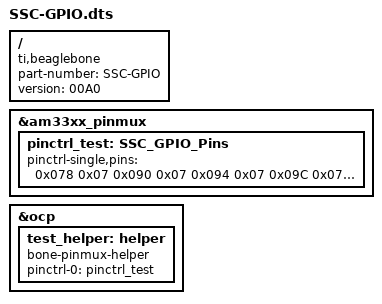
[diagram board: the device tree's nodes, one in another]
/*  
* Copyright (C) 2012 Texas Instruments Incorporated - http://www.ti.com/
*
* This program is free software; you can redistribute it and/or modify
* it under the terms of the GNU General Purpose License Version 2 as
* published by the Free Software Foundation
*
* Original from: github.com/jadonk/validation-scripts/blob/master/test-capemgr/ 
*
* Modified by Derek Molloy for the example on www.derekmolloy.ie
* that maps GPIO pins for the example
* 
* Final Edits by Brandon Marick
* 1/19/2014
*/

/dts-v1/;
/plugin/;

/{
       compatible = "ti,beaglebone", "ti,beaglebone-black";
       part-number = "SSC-GPIO";
       version = "00A0";

       fragment@0 {
             target = <&am33xx_pinmux>;
            
             __overlay__ {
                  pinctrl_test: SSC_GPIO_Pins {
			pinctrl-single,pins = <

				0x078 0x07  /* P9_12 60 OUTPUT MODE7 - The LED Output */
								
				0x090 0x07  /* P8_07 66 OUTPUT MODE7 */
				0x094 0x07  /* P8_08 67 OUTPUT MODE7 */
				0x09C 0x07  /* P8_09 69 OUTPUT MODE7 */
				0x098 0x07  /* P8_10 68 OUTPUT MODE7 */
				0x034 0x07  /* P8_11 45 OUTPUT MODE7 */
				0x030 0x07  /* P8_12 44 OUTPUT MODE7 */
				0x024 0x07  /* P8_13 23 OUTPUT MODE7 */
				0x028 0x07  /* P8_14 26 OUTPUT MODE7 */
				0x03C 0x07  /* P8_15 47 OUTPUT MODE7 */
				0x038 0x07  /* P8_16 46 OUTPUT MODE7 */
				0x02C 0x07  /* P8_17 27 OUTPUT MODE7 */
				0x08C 0x07  /* P8_18 65 OUTPUT MODE7 */

                               /* OUTPUT  GPIO(mode7) 0x07 pulldown, 0x17 pullup, 0x?f no pullup/down */
			       /* INPUT   GPIO(mode7) 0x27 pulldown, 0x37 pullup, 0x?f no pullup/down */

			>;
		  };
             };
       };

       fragment@1 {
		target = <&ocp>;
		__overlay__ {
			test_helper: helper {
				compatible = "bone-pinmux-helper";
				pinctrl-names = "default";
				pinctrl-0 = <&pinctrl_test>;
				status = "okay";
			};
		};
	};
};
